# GD32H77x_78x register map
File version: 1.0
CPU: CM7 r1p2, little endian, MPU, FPU, 4 interrupt priority bits
Registers are 32-bit, read-write, reset 0x0 unless marked. A register's access mark holds for its fields unless they carry their own. Offsets are from the block's base; [hi:lo] are bit positions; lines under a group give offsets from that group; {n}, {i} and the like mark numbered series; 'fields as' and 'values as' point back to an identical list.

## HPDF — High Performance Digital Filter
Base 0x40017000
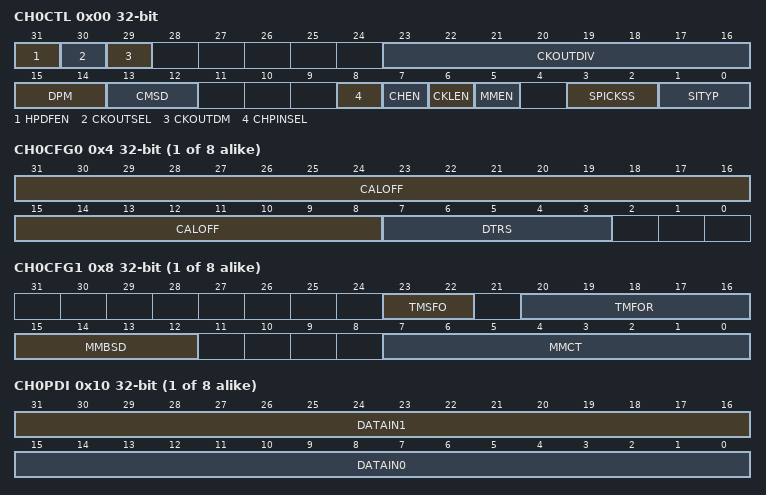
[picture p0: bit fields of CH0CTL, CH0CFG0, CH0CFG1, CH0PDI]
0x00 CH0CTL — Channel 0 control regist
  [31] HPDFEN — Global enable for HPDF interface 0: HPDF disabled
  [30] CKOUTSEL — Serial clock output source selection
  [29] CKOUTDM — Serial clock output duty mode
  [23:16] CKOUTDIV — Serial clock output divider
  [15:14] DPM — Data packing mode for HPDF_CHxPDI register
  [13:12] CMSD — Channel x multiplexer select input data source
  [8] CHPINSEL — Channel inputs pins selection
  [7] CHEN — Channel x enable
  [6] CKLEN — Clock loss detector enable
  [5] MMEN — Malfunction monitor enable
  [3:2] SPICKSS — SPI clock source select
  [1:0] SITYP — Serial interface type
{0x4+0x20*i} CH{i}CFG0 (i=0..7) — Channel {i} configuration register
  [31:8] CALOFF — 24-bit calibration offset
  [7:3] DTRS — Data right bit-shift
{0x8+0x20*i} CH{i}CFG1 (i=0..7) — Channel {i} configuration register
  [23:22] TMSFO — Threshold monitor Sinc filter order selection
  [20:16] TMFOR — Threshold monitor filter oversampling rate (decimation rate)
  [15:12] MMBSD — Malfunction monitor break signal distribution
  [7:0] MMCT — Malfunction monitor counter threshold
{0xC+0x20*i} CH{i}TMFDT ro (i=0..7) — Channel {i} threshold monitor filter data regist
  [15:0] TMDATA — Threshold monitor data
{0x10+0x20*i} CH{i}PDI (i=0..7) — Channel {i} parallel data input regist
  [31:16] DATAIN1 — Data input for channel x or channel x+1
  [15:0] DATAIN0 — Data input for channel x
{0x14+0x20*i} CH{i}PS (i=0..7) — Channel {i} pulse skip regist
  [5:0] PLSK — Pulses to skip for input data skipping function
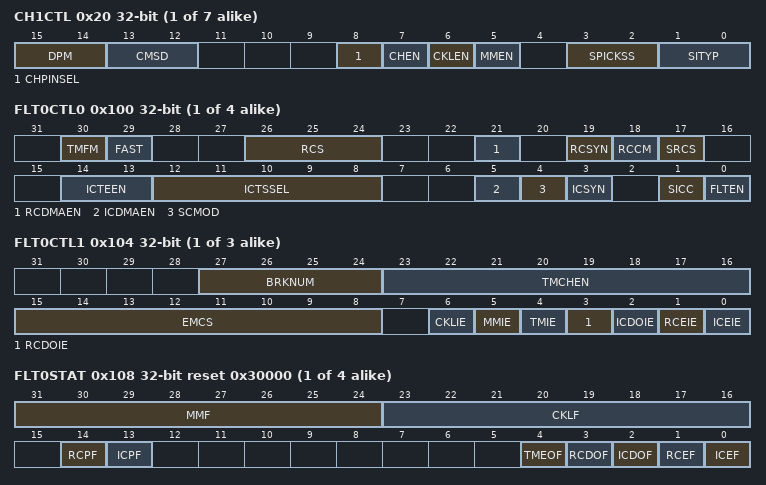
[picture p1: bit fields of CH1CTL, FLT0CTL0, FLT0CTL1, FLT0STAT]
{0x0+0x20*i} CH{i}CTL (i=1..7) — Channel {i} control regist
  [15:14] DPM — Data packing mode for HPDF_CHxPDI register
  [13:12] CMSD — Channel x multiplexer select input data source
  [8] CHPINSEL — Channel inputs pins selection
  [7] CHEN — Channel x enable
  [6] CKLEN — Clock loss detector enable
  [5] MMEN — Malfunction monitor enable
  [3:2] SPICKSS — SPI clock source select
  [1:0] SITYP — Serial interface type
{0x100+0x80*i} FLT{i}CTL0 (i=0..3) — Filter {i} control register
  [30] TMFM — Threshold monitor fast mode
  [29] FAST — Fast conversion mode for regular conversions
  [26:24] RCS — Regular conversion channel selection
  [21] RCDMAEN — DMA channel enabled to read data for the regular conversion
  [19] RCSYN — Regular conversion synchronously with HPDF_FLT0
  [18] RCCM — Regular conversions continuous mode
  [17] SRCS — Start regular channel conversion by software
  [14:13] ICTEEN — Inserted conversions trigger edge enable
  [12:8] ICTSSEL — Inserted conversions trigger signal selection
  [5] ICDMAEN — DMA channel enabled to read data for the inserted channel group
  [4] SCMOD — Scan conversion mode of inserted conversions
  [3] ICSYN — Inserted conversion synchronously with the HPDF_FLT0 SICC trigger
  [1] SICC — Start inserted group channel conversion
  [0] FLTEN — HPDF_FLTy enable
{0x104+0x80*i} FLT{i}CTL1 (i=0..2) — Filter {i} control register
  [27:24] BRKNUM — Break signal number configuration
  [23:16] TMCHEN — Threshold monitor channel enable
  [15:8] EMCS — Extremes monitor channel selection
  [6] CKLIE — Clock loss interrupt enable
  [5] MMIE — Malfunction monitor interrupt enable
  [4] TMIE — Threshold monitor interrupt enable
  [3] RCDOIE — Regular conversion data overflow interrupt enable
  [2] ICDOIE — Inserted conversion data overflow interrupt enable
  [1] RCEIE — Regular conversion end interrupt enable
  [0] ICEIE — Inserted conversion end interrupt enable
{0x108+0x80*i} FLT{i}STAT ro reset 0x30000 (i=0..3) — Filter {i} status regist
  [31:24] MMF — Malfunction monitor flag
  [23:16] CKLF — Clock loss flag
  [14] RCPF — Regular conversion in progress flag
  [13] ICPF — Inserted conversion in progress flag
  [4] TMEOF — Threshold monitor event occurred flag
  [3] RCDOF — Regular conversion data overflow flag
  [2] ICDOF — Inserted conversion data overflow flag
  [1] RCEF — Regular conversion end flag
  [0] ICEF — Inserted conversion end flag
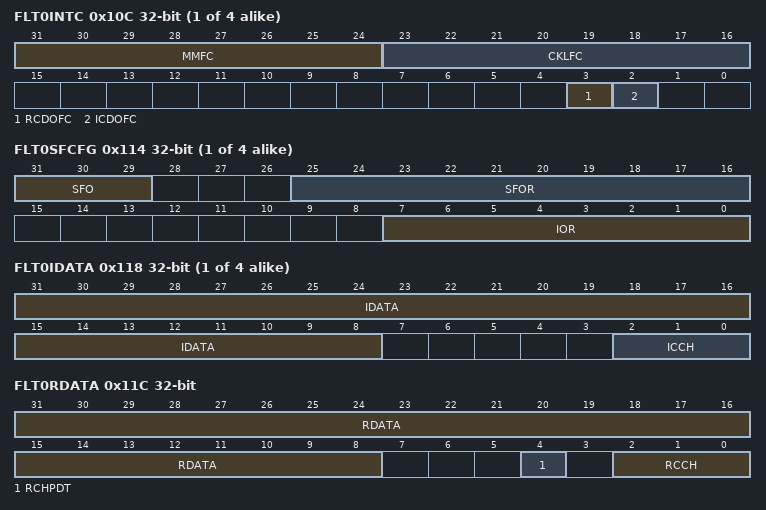
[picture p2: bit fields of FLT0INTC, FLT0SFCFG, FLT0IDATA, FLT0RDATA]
{0x10C+0x80*i} FLT{i}INTC (i=0..3) — Filter {i} interrupt flag clear regist
  [31:24] MMFC — Clear the malfunction monitor flag
  [23:16] CKLFC — Clear the clock loss flag
  [3] RCDOFC — Clear the regular conversion data overflow flag
  [2] ICDOFC — Clear the inserted conversion data overflow flag
{0x110+0x80*i} FLT{i}ICGS reset 0x1 (i=0..3) — Filter {i} inserted channel group selection regist
  [7:0] ICGSEL — Inserted channel group selection
{0x114+0x80*i} FLT{i}SFCFG (i=0..3) — Filter {i} sinc filter configuration regist
  [31:29] SFO — Sinc filter order
  [25:16] SFOR — Sinc filter oversampling ratio (decimation rate)
  [7:0] IOR — Integrator oversampling ratio
{0x118+0x80*i} FLT{i}IDATA ro (i=0..3) — Filter {i} inserted group conversion data regist
  [31:8] IDATA — Inserted group conversion data
  [2:0] ICCH — Inserted channel most recently converted
0x11C FLT0RDATA ro — Filter 0 regular channel conversion data regist
  [31:8] RDATA — Regular channel conversion data
  [4] RCHPDT — Regular channel pending data
  [2:0] RCCH — Regular channel most recently converted
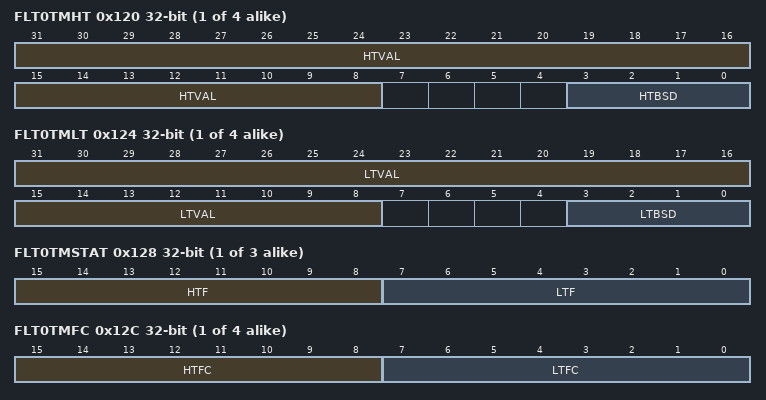
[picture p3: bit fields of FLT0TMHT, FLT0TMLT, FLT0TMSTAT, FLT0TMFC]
{0x120+0x80*i} FLT{i}TMHT (i=0..3) — Filter {i} threshold monitor high threshold regist
  [31:8] HTVAL — Threshold monitor high threshold value
  [3:0] HTBSD — High threshold event break signal distribution
{0x124+0x80*i} FLT{i}TMLT (i=0..3) — Filter {i} threshold monitor low threshold regist
  [31:8] LTVAL — Threshold monitor low threshold value
  [3:0] LTBSD — Low threshold event break signal distribution
{0x128+0x80*i} FLT{i}TMSTAT ro (i=0..2) — Filter {i} threshold monitor status regist
  [15:8] HTF — Threshold monitor high threshold flag
  [7:0] LTF — Threshold monitor low threshold flag
{0x12C+0x80*i} FLT{i}TMFC (i=0..3) — Filter {i} threshold monitor flag clear regist
  [15:8] HTFC — Clear the threshold monitor high threshold flag
  [7:0] LTFC — Clear the threshold monitor low threshold flag
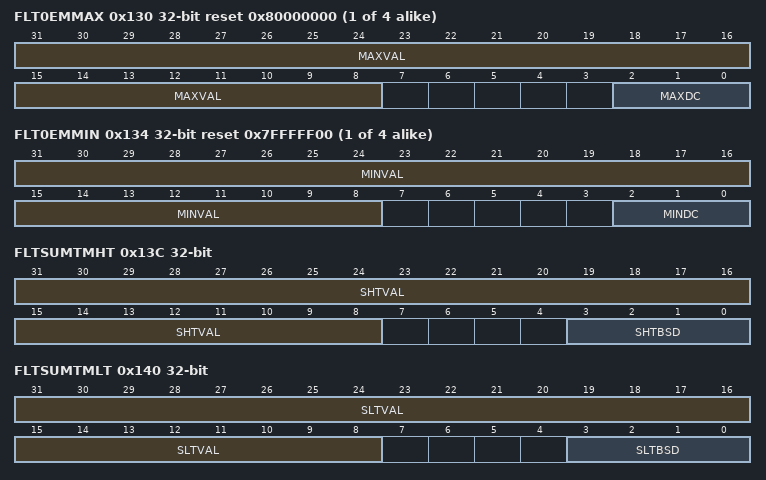
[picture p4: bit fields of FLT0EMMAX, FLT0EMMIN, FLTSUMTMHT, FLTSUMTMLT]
{0x130+0x80*i} FLT{i}EMMAX ro reset 0x80000000 (i=0..3) — Filter {i} extremes monitor maximum regist
  [31:8] MAXVAL — Extremes monitor maximum value
  [2:0] MAXDC — Extremes monitor maximum data channel
{0x134+0x80*i} FLT{i}EMMIN ro reset 0x7FFFFF00 (i=0..3) — Filter {i} extremes monitor minimum regist
  [31:8] MINVAL — Extremes monitor minimum value
  [2:0] MINDC — Extremes monitor minimum data channel
{0x138+0x80*i} FLT{i}CT ro (i=0..2) — Filter {i} conversion timer register
  [31:4] CTCNT — Extremes monitor minimum value
0x13C FLTSUMTMHT — Filter sum threshold monitor high threshold register
  [31:8] SHTVAL — Filter sum threshold monitor high threshold value
  [3:0] SHTBSD — High sum threshold event break signal distribution
0x140 FLTSUMTMLT — Filter sum threshold monitor low threshold register
  [31:8] SLTVAL — Filter sum threshold monitor low threshold value
  [3:0] SLTBSD — low sum threshold event break signal distribution
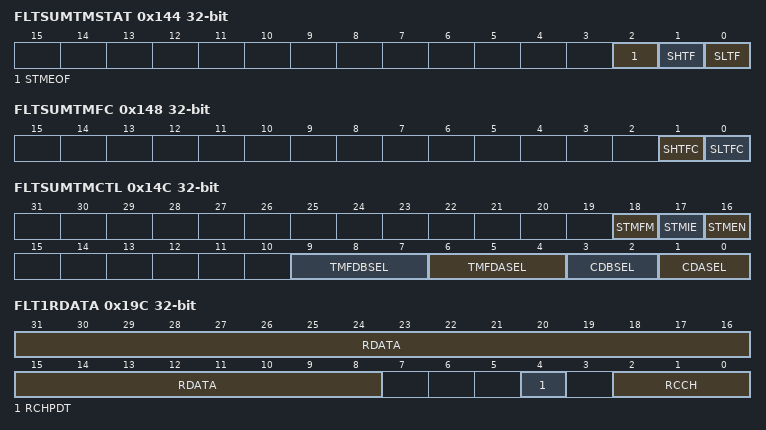
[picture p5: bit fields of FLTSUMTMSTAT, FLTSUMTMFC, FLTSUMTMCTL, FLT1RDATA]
0x144 FLTSUMTMSTAT ro — Filter sum threshold monitor status register
  [2] STMEOF — Sum threshold monitor event occurred flag
  [1] SHTF — Sum threshold monitor high threshold flag
  [0] SLTF — Sum threshold monitor low threshold flag
0x148 FLTSUMTMFC — Filter sum threshold monitor flag clear register
  [1] SHTFC — Clear the sum threshold monitor high threshold flag
  [0] SLTFC — Clear the sum threshold monitor high threshold flag
0x14C FLTSUMTMCTL — Filter sum control register
  [18] STMFM — Sum threshold monitor fast mode
  [17] STMIE — Sum threshold monitor interrupt enable
  [16] STMEN — Sum threshold monitor enable
  [9:7] TMFDBSEL — The data for the input phase B of the addition is selected from the serial data stream
  [6:4] TMFDASEL — The data for the input phase A of the addition is selected from the serial data stream
  [3:2] CDBSEL — The data for the input phase B of the addition is selected from the final output data
  [1:0] CDASEL — The data for the input phase A of the addition is selected from the final output data
0x19C FLT1RDATA ro — Filter 1 regular channel conversion data regist
  fields as FLT0RDATA
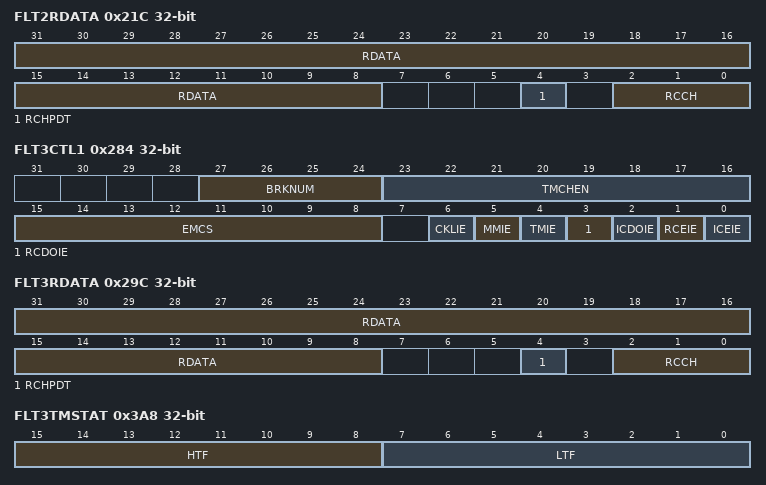
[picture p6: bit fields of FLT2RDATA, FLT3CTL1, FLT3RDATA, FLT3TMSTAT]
0x21C FLT2RDATA ro — Filter 0 regular channel conversion data regist
  fields as FLT0RDATA
0x284 FLT3CTL1 — Filter 2 control register
  fields as FLT0CTL1
0x29C FLT3RDATA ro — Filter 3 regular channel conversion data regist
  fields as FLT0RDATA
0x2B8 FLT3CT ro — Filter 3 conversion timer register
  [31:4] CTCNT — Timer counting conversion time
0x3A8 FLT3TMSTAT ro — Filter 3 threshold monitor status regist
  fields as FLT0TMSTAT
